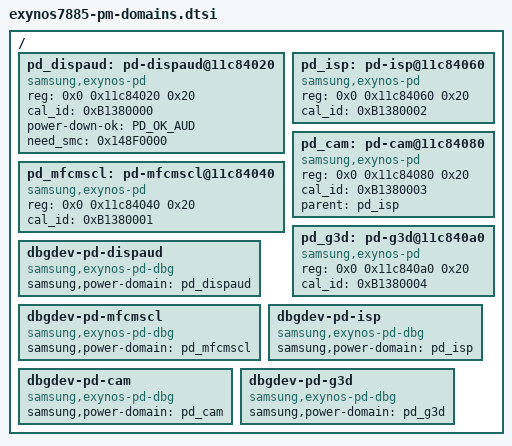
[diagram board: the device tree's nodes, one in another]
/*
 * SAMSUNG EXYNOS7872 SoC PM Domains device tree source
 *
 * Copyright (c) 2016 Samsung Electronics Co., Ltd.
 *		http://www.samsung.com
 *
 * SAMSUNG EXYNOS7872 SoC PM domains device nodes are listed in this file.
 * EXYNOS7872 based board files can include this file and provide
 * values for board specfic bindings.
 *
 * This program is free software; you can redistribute it and/or modify
 * it under the terms of the GNU General Public License version 2 as
 * published by the Free Software Foundation.
 */
#include <dt-bindings/power/exynos-power.h>

/ {
	pd_dispaud: pd-dispaud@11c84020 {
		compatible = "samsung,exynos-pd";
		reg = <0x0 0x11c84020 0x20>;
		cal_id = <0xB1380000>;
		status = "okay";
		power-down-ok = <PD_OK_AUD>;
		need_smc = <0x148F0000>;
	};

	pd_mfcmscl: pd-mfcmscl@11c84040 {
		compatible = "samsung,exynos-pd";
		reg = <0x0 0x11c84040 0x20>;
		cal_id = <0xB1380001>;
		status = "okay";
	};

	pd_isp: pd-isp@11c84060 {
		compatible = "samsung,exynos-pd";
		reg = <0x0 0x11c84060 0x20>;
		cal_id = <0xB1380002>;
		status = "okay";
	};

	pd_cam: pd-cam@11c84080 {
		compatible = "samsung,exynos-pd";
		reg = <0x0 0x11c84080 0x20>;
		cal_id = <0xB1380003>;
		status = "okay";
		parent = <&pd_isp>;
	};

	pd_g3d: pd-g3d@11c840a0 {
		compatible = "samsung,exynos-pd";
		reg = <0x0 0x11c840a0 0x20>;
		cal_id = <0xB1380004>;
		status = "okay";
	};

	dbgdev-pd-dispaud {
		compatible = "samsung,exynos-pd-dbg";
		samsung,power-domain = <&pd_dispaud>;
	};

	dbgdev-pd-mfcmscl {
		compatible = "samsung,exynos-pd-dbg";
		samsung,power-domain = <&pd_mfcmscl>;
	};

	dbgdev-pd-isp {
		compatible = "samsung,exynos-pd-dbg";
		samsung,power-domain = <&pd_isp>;
	};

	dbgdev-pd-cam {
		compatible = "samsung,exynos-pd-dbg";
		samsung,power-domain = <&pd_cam>;
	};

	dbgdev-pd-g3d {
		compatible = "samsung,exynos-pd-dbg";
		samsung,power-domain = <&pd_g3d>;
	};

};
